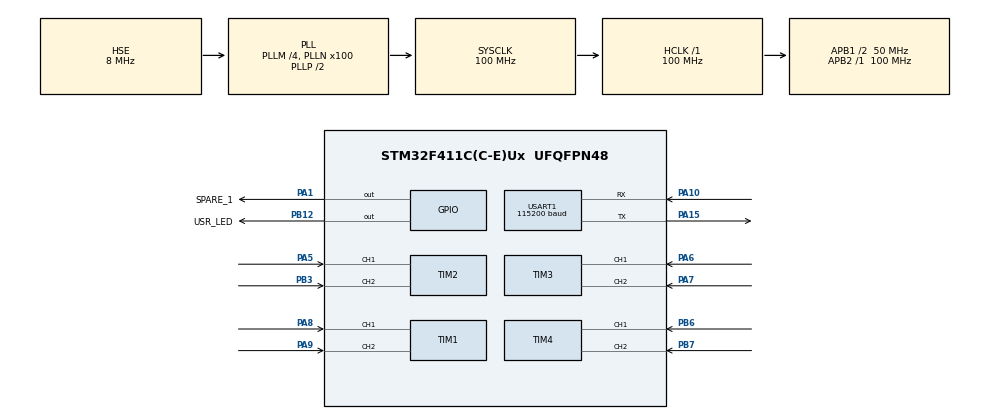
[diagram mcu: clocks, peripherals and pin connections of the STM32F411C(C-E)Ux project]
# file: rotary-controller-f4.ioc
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FREERTOS.Tasks01=defaultTask,24,128,StartDefaultTask,Default,NULL,Dynamic,NULL,NULL
FREERTOS.configENABLE_FPU=1
FREERTOS.configUSE_NEWLIB_REENTRANT=1
Mcu.Family=STM32F4
Mcu.Name=STM32F411C(C-E)Ux
Mcu.Package=UFQFPN48
NVIC.PriorityGroup=NVIC_PRIORITYGROUP_4
NVIC.TIM1_BRK_TIM9_IRQn=true\:5\:0\:true\:false\:true\:false\:true\:true\:true
NVIC.TIM1_TRG_COM_TIM11_IRQn=true\:15\:0\:true\:false\:true\:false\:false\:true\:true
NVIC.TIM1_UP_TIM10_IRQn=true\:15\:0\:true\:false\:true\:false\:true\:true\:true
NVIC.TimeBase=TIM1_TRG_COM_TIM11_IRQn
NVIC.TimeBaseIP=TIM11
NVIC.USART1_IRQn=true\:15\:0\:true\:false\:true\:true\:true\:true\:true
PA1.GPIO_Label=SPARE_1
PA1.Signal=GPIO_Output
PA10.Mode=Asynchronous
PA10.Signal=USART1_RX
PA13.Mode=Serial_Wire
PA13.Signal=SYS_JTMS-SWDIO
PA14.Mode=Serial_Wire
PA14.Signal=SYS_JTCK-SWCLK
PA15.Mode=Asynchronous
PA15.Signal=USART1_TX
PA5.GPIO_PuPd=GPIO_PULLUP
PA5.GPIO_Speed=GPIO_SPEED_FREQ_VERY_HIGH
PA5.Signal=S_TIM2_CH1_ETR
PA6.GPIO_PuPd=GPIO_PULLUP
PA6.GPIO_Speed=GPIO_SPEED_FREQ_VERY_HIGH
PA6.Signal=S_TIM3_CH1
PA7.GPIO_PuPd=GPIO_PULLUP
PA7.GPIO_Speed=GPIO_SPEED_FREQ_VERY_HIGH
PA7.Signal=S_TIM3_CH2
PA8.GPIO_PuPd=GPIO_PULLUP
PA8.GPIO_Speed=GPIO_SPEED_FREQ_VERY_HIGH
PA8.Signal=S_TIM1_CH1
PA9.GPIO_PuPd=GPIO_PULLUP
PA9.GPIO_Speed=GPIO_SPEED_FREQ_VERY_HIGH
PA9.Signal=S_TIM1_CH2
PB12.GPIO_Label=USR_LED
PB12.GPIO_Speed=GPIO_SPEED_FREQ_MEDIUM
PB12.PinState=GPIO_PIN_SET
PB12.Signal=GPIO_Output
PB3.GPIO_PuPd=GPIO_PULLUP
PB3.GPIO_Speed=GPIO_SPEED_FREQ_VERY_HIGH
PB3.Signal=S_TIM2_CH2
PB6.GPIO_PuPd=GPIO_PULLUP
PB6.GPIO_Speed=GPIO_SPEED_FREQ_VERY_HIGH
PB6.Signal=S_TIM4_CH1
PB7.GPIO_PuPd=GPIO_PULLUP
PB7.GPIO_Speed=GPIO_SPEED_FREQ_VERY_HIGH
PB7.Signal=S_TIM4_CH2
PH0\ -\ OSC_IN.Mode=HSE-External-Oscillator
PH0\ -\ OSC_IN.Signal=RCC_OSC_IN
PH1\ -\ OSC_OUT.Mode=HSE-External-Oscillator
PH1\ -\ OSC_OUT.Signal=RCC_OSC_OUT
ProjectManager.HeapSize=0x200
ProjectManager.StackSize=0x400
ProjectManager.TargetToolchain=STM32CubeIDE
RCC.48MHZClocksFreq_Value=50000000
RCC.AHBFreq_Value=100000000
RCC.APB1CLKDivider=RCC_HCLK_DIV2
RCC.APB1Freq_Value=50000000
RCC.APB1TimFreq_Value=100000000
RCC.APB2Freq_Value=100000000
RCC.APB2TimFreq_Value=100000000
RCC.CortexFreq_Value=100000000
RCC.HCLKFreq_Value=100000000
RCC.HSE_Timout=1000
RCC.HSE_VALUE=8000000
RCC.HSI_VALUE=16000000
RCC.LSE_VALUE=32768
RCC.PLLM=4
RCC.PLLN=100
RCC.PLLSourceVirtual=RCC_PLLSOURCE_HSE
RCC.SYSCLKFreq_VALUE=100000000
RCC.SYSCLKSource=RCC_SYSCLKSOURCE_PLLCLK
RCC.VCOOutputFreq_Value=200000000
SH.S_TIM1_CH1.0=TIM1_CH1,Encoder_Interface
SH.S_TIM1_CH2.0=TIM1_CH2,Encoder_Interface
SH.S_TIM2_CH1_ETR.0=TIM2_CH1,Encoder_Interface
SH.S_TIM2_CH2.0=TIM2_CH2,Encoder_Interface
SH.S_TIM3_CH1.0=TIM3_CH1,Encoder_Interface
SH.S_TIM3_CH2.0=TIM3_CH2,Encoder_Interface
SH.S_TIM4_CH1.0=TIM4_CH1,Encoder_Interface
SH.S_TIM4_CH2.0=TIM4_CH2,Encoder_Interface
TIM1.EncoderMode=TIM_ENCODERMODE_TI12
TIM2.EncoderMode=TIM_ENCODERMODE_TI12
TIM3.EncoderMode=TIM_ENCODERMODE_TI12
TIM4.EncoderMode=TIM_ENCODERMODE_TI12
TIM9.Period=20-1
TIM9.Prescaler=100 -1
USART1.BaudRate=115200
USART1.OverSampling=UART_OVERSAMPLING_16
USART1.VirtualMode=VM_ASYNC
VP_FREERTOS_VS_CMSIS_V2.Mode=CMSIS_V2
VP_SYS_VS_tim11.Mode=TIM11
VP_TIM9_VS_ClockSourceINT.Mode=Internal
board=custom

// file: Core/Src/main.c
/* USER CODE BEGIN Header */
/**
  ******************************************************************************
  * @file           : main.c
  * @brief          : Main program body
  ******************************************************************************
  * @attention
  *
  * Copyright (c) 2022 STMicroelectronics.
  * All rights reserved.
  *
  * This software is licensed under terms that can be found in the LICENSE file
  * in the root directory of this software component.
  * If no LICENSE file comes with this software, it is provided AS-IS.
  *
  ******************************************************************************
  */
/* USER CODE END Header */
#include "main.h"
#include "cmsis_os.h"
#include "tim.h"
#include "usart.h"
#include "gpio.h"

/* USER CODE BEGIN PV */
rampsHandler_t RampsData;
/* USER CODE END PV */

void SystemClock_Config(void);
void MX_FREERTOS_Init(void);

int main(void)
{

  /* MCU Configuration--------------------------------------------------------*/

  /* Reset of all peripherals, Initializes the Flash interface and the Systick. */
  HAL_Init();

  /* Configure the system clock */
  SystemClock_Config();

  /* Initialize all configured peripherals */
  MX_GPIO_Init();
  MX_TIM1_Init();
  MX_TIM2_Init();
  MX_TIM3_Init();
  MX_TIM4_Init();
  MX_USART1_UART_Init();
  MX_TIM9_Init();
  /* USER CODE BEGIN 2 */
  // htim1 is used in encoder mode
  // htim2 is used in encoder mode
  // htim3 is used in encoder mode
  // htim4 is used in encoder mode
  // htim9 is used to generate the synchro motion

  RampsData.scaleTimers[0] = &htim1;
  RampsData.scaleTimers[1] = &htim2;
  RampsData.scaleTimers[2] = &htim3;
  RampsData.scaleTimers[3] = &htim4;
  RampsData.synchroRefreshTimer = &htim9;
  RampsData.modbusUart = &huart1;
  RampsStart(&RampsData);

  /* USER CODE END 2 */

  /* Init scheduler */
  osKernelInitialize();

  /* Call init function for freertos objects (in freertos.c) */
  MX_FREERTOS_Init();

  /* Start scheduler */
  osKernelStart();

  /* We should never get here as control is now taken by the scheduler */
  /* Infinite loop */
  while (1)
  {

  }
}

void SystemClock_Config(void)
{
  RCC_OscInitTypeDef RCC_OscInitStruct = {0};
  RCC_ClkInitTypeDef RCC_ClkInitStruct = {0};

  /** Configure the main internal regulator output voltage
  */
  __HAL_RCC_PWR_CLK_ENABLE();
  __HAL_PWR_VOLTAGESCALING_CONFIG(PWR_REGULATOR_VOLTAGE_SCALE1);

  /** Initializes the RCC Oscillators according to the specified parameters
  * in the RCC_OscInitTypeDef structure.
  */
  RCC_OscInitStruct.OscillatorType = RCC_OSCILLATORTYPE_HSE;
  RCC_OscInitStruct.HSEState = RCC_HSE_ON;
  RCC_OscInitStruct.PLL.PLLState = RCC_PLL_ON;
  RCC_OscInitStruct.PLL.PLLSource = RCC_PLLSOURCE_HSE;
  RCC_OscInitStruct.PLL.PLLM = 4;
  RCC_OscInitStruct.PLL.PLLN = 100;
  RCC_OscInitStruct.PLL.PLLP = RCC_PLLP_DIV2;
  RCC_OscInitStruct.PLL.PLLQ = 4;
  if (HAL_RCC_OscConfig(&RCC_OscInitStruct) != HAL_OK)
  {
    Error_Handler();
  }

  /** Initializes the CPU, AHB and APB buses clocks
  */
  RCC_ClkInitStruct.ClockType = RCC_CLOCKTYPE_HCLK|RCC_CLOCKTYPE_SYSCLK
                              |RCC_CLOCKTYPE_PCLK1|RCC_CLOCKTYPE_PCLK2;
  RCC_ClkInitStruct.SYSCLKSource = RCC_SYSCLKSOURCE_PLLCLK;
  RCC_ClkInitStruct.AHBCLKDivider = RCC_SYSCLK_DIV1;
  RCC_ClkInitStruct.APB1CLKDivider = RCC_HCLK_DIV2;
  RCC_ClkInitStruct.APB2CLKDivider = RCC_HCLK_DIV1;

  if (HAL_RCC_ClockConfig(&RCC_ClkInitStruct, FLASH_LATENCY_3) != HAL_OK)
  {
    Error_Handler();
  }
}

void HAL_TIM_PeriodElapsedCallback(TIM_HandleTypeDef *htim)
{
  if (htim->Instance == TIM11) {
    HAL_IncTick();
  }
}

void Error_Handler(void)
{
  __disable_irq();
  while (1)
  {
  }
}

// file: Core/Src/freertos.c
/* USER CODE BEGIN Header */
/**
  ******************************************************************************
  * File Name          : freertos.c
  * Description        : Code for freertos applications
  ******************************************************************************
  * @attention
  *
  * Copyright (c) 2022 STMicroelectronics.
  * All rights reserved.
  *
  * This software is licensed under terms that can be found in the LICENSE file
  * in the root directory of this software component.
  * If no LICENSE file comes with this software, it is provided AS-IS.
  *
  ******************************************************************************
  */
/* USER CODE END Header */

#include "FreeRTOS.h"
#include "task.h"
#include "main.h"
#include "cmsis_os.h"

/* Definitions for defaultTask */
osThreadId_t defaultTaskHandle;
const osThreadAttr_t defaultTask_attributes = {
  .name = "defaultTask",
  .stack_size = 128 * 4,
  .priority = (osPriority_t) osPriorityNormal,
};

void StartDefaultTask(void *argument);

void MX_FREERTOS_Init(void); /* (MISRA C 2004 rule 8.1) */

void MX_FREERTOS_Init(void) {

  /* Create the thread(s) */
  /* creation of defaultTask */
  defaultTaskHandle = osThreadNew(StartDefaultTask, NULL, &defaultTask_attributes);

}

void StartDefaultTask(void *argument)
{
  /* USER CODE BEGIN StartDefaultTask */
  /* Infinite loop */
  for(;;)
  {
    osDelay(10000);
  }
  /* USER CODE END StartDefaultTask */
}
